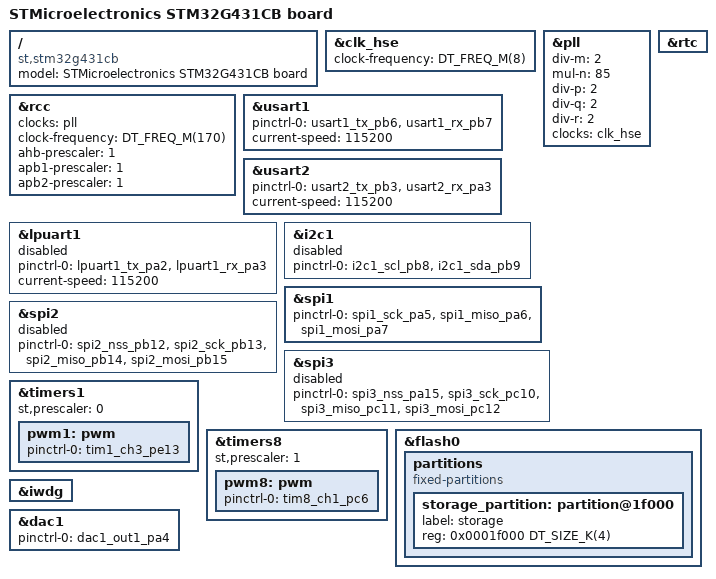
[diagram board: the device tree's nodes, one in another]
/*
 * Copyright (c) 2019 Richard Osterloh <richard.osterloh@gmail.com>
 *
 * SPDX-License-Identifier: Apache-2.0
 */

/dts-v1/;
#include <st/g4/stm32g431Xb.dtsi>
#include <st/g4/stm32g431r(6-8-b)tx-pinctrl.dtsi>
#include "arduino_r3_connector.dtsi"
#include <zephyr/dt-bindings/adc/adc.h>

/ {
	model = "STMicroelectronics STM32G431CB board";
	compatible = "st,stm32g431cb";
};

&clk_hse {
	clock-frequency = <DT_FREQ_M(8)>;
	status = "okay";
};

&pll {
	div-m = <2>;
	mul-n = <85>;
	div-p = <2>;
	div-q = <2>;
	div-r = <2>;
	clocks = <&clk_hse>;
	status = "okay";
};

&rcc {
	clocks = <&pll>;
	clock-frequency = <DT_FREQ_M(170)>;
	ahb-prescaler = <1>;
	apb1-prescaler = <1>;
	apb2-prescaler = <1>;
};

&usart1 {
	pinctrl-0 = <&usart1_tx_pb6 &usart1_rx_pb7>;
	pinctrl-names = "default";
	current-speed = <115200>;
	status = "okay";
};

&usart2 {
	pinctrl-0 = <&usart2_tx_pb3 &usart2_rx_pa3>;
	pinctrl-names = "default";
	current-speed = <115200>;
	status = "okay";
};

&lpuart1 {
	pinctrl-0 = <&lpuart1_tx_pa2 &lpuart1_rx_pa3>;
	pinctrl-names = "default";
	current-speed = <115200>;
	status = "disabled";
};

&i2c1 {
	pinctrl-0 = <&i2c1_scl_pb8 &i2c1_sda_pb9>;
	pinctrl-names = "default";
	status = "disabled";
};

&spi1 {
	pinctrl-0 = <&spi1_sck_pa5 &spi1_miso_pa6 &spi1_mosi_pa7>;
	pinctrl-names = "default";
	status = "okay";
};

&spi2 {
	pinctrl-0 = <&spi2_nss_pb12 &spi2_sck_pb13
		     &spi2_miso_pb14 &spi2_mosi_pb15>;
	pinctrl-names = "default";
	status = "disabled";
};

&spi3 {
	/* SPI3 on the ST Morpho Connector CN7 pins 17, 1, 2, 3*/
	pinctrl-0 = <&spi3_nss_pa15 &spi3_sck_pc10
		     &spi3_miso_pc11 &spi3_mosi_pc12>;
	pinctrl-names = "default";
	status = "disabled";
};

&timers1 {
	st,prescaler = <0>;
	status = "okay";

	pwm1: pwm {
		status = "okay";
		pinctrl-0 = <&tim1_ch3_pe13>;
		pinctrl-names = "default";
	};
};

&timers8 {
	st,prescaler = <1>;
	status = "okay";

	pwm8: pwm {
		status = "okay";
		pinctrl-0 = <&tim8_ch1_pc6>;
		pinctrl-names = "default";
	};
};

&rtc {
	status = "okay";
};

&flash0 {

	partitions {
		compatible = "fixed-partitions";
		#address-cells = <1>;
		#size-cells = <1>;

		/* Set 4Kb of storage at the end of the 128Kb of flash */
		storage_partition: partition@1f000 {
			label = "storage";
			reg = <0x0001f000 DT_SIZE_K(4)>;
		};
	};
};

&iwdg {
	status = "okay";
};

&dac1 {
	status = "okay";
	pinctrl-0 = <&dac1_out1_pa4>;
	pinctrl-names = "default";
};
